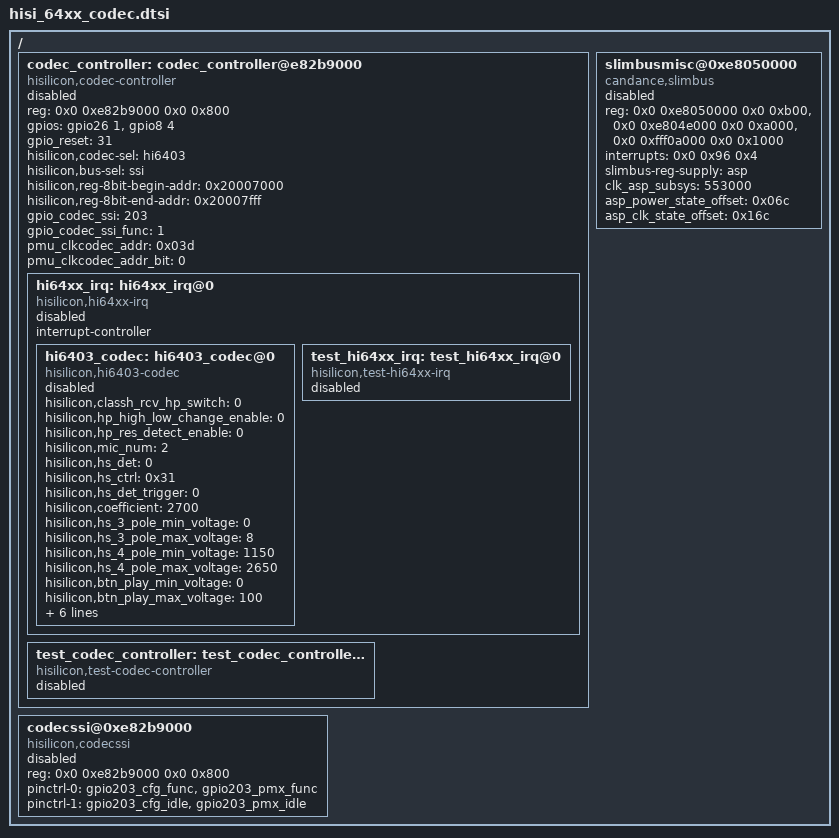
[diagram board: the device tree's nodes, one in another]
/*
 *  Copyright (C) 2014 Hisilicon Ltd.
 *
 *  This program is free software; you can redistribute it and/or modify
 *  it under the terms of the GNU General Public License version 2 as
 *  publishhed by the Free Software Foundation.
 */

/ {
	codec_controller: codec_controller@e82b9000 {
		compatible = "hisilicon,codec-controller";
		/* ssi base-addr & addr-range(0x200 << 2) */
		reg = <0x0 0xe82b9000 0x0 0x800>;
		/* irq & reset */
		gpios = <&gpio26 1 0>, <&gpio8 4 0>;
		gpio_reset = <31>; /* GPIO_031*/
		/* ssi pinctrl */
		/* select slimbus or ssi */
		hisilicon,codec-sel = "hi6403";
		hisilicon,bus-sel = "ssi";
		hisilicon,reg-8bit-begin-addr = <0x20007000>;
		hisilicon,reg-8bit-end-addr = <0x20007fff>;
		gpio_codec_ssi = <203>;
		gpio_codec_ssi_func = <1>;
		pmu_clkcodec_addr = <0x03d>;
		pmu_clkcodec_addr_bit = <0>;
		status = "disabled";

		hi64xx_irq: hi64xx_irq@0 {
			compatible = "hisilicon,hi64xx-irq";
			#interrupt-cells = <2>;
			interrupt-controller;
			status = "disabled";

			hi6403_codec: hi6403_codec@0{
				compatible = "hisilicon,hi6403-codec";
				hisilicon,classh_rcv_hp_switch = <0>;
				hisilicon,hp_high_low_change_enable = <0>;
				hisilicon,hp_res_detect_enable = <0>;
				hisilicon,mic_num = <2>;
				hisilicon,hs_det = <0>;
				hisilicon,hs_ctrl = <0x31>;
				hisilicon,hs_det_trigger = <0>;
				hisilicon,coefficient = <2700>;
				hisilicon,hs_3_pole_min_voltage = <0>;
				hisilicon,hs_3_pole_max_voltage = <8>;
				hisilicon,hs_4_pole_min_voltage = <1150>;
				hisilicon,hs_4_pole_max_voltage = <2650>;
				hisilicon,btn_play_min_voltage = <0>;
				hisilicon,btn_play_max_voltage = <100>;
				hisilicon,btn_voice_assistant_min_voltage = <110>;
				hisilicon,btn_voice_assistant_max_voltage = <180>;
				hisilicon,btn_volume_up_min_voltage = <181>;
				hisilicon,btn_volume_up_max_voltage = <320>;
				hisilicon,btn_volume_down_min_voltage = <320>;
				hisilicon,btn_volume_down_max_voltage = <700>;
				status = "disabled";
			};

			test_hi64xx_irq: test_hi64xx_irq@0 {
                               compatible = "hisilicon,test-hi64xx-irq";
                               status = "disabled";
			};
		};

		test_codec_controller: test_codec_controller@0 {
			compatible = "hisilicon,test-codec-controller";
			status = "disabled";
		};
	};
	codecssi@0xe82b9000 {
		compatible = "hisilicon,codecssi";
		reg = <0x0 0xe82b9000 0x0 0x800>;
		/* ssi pinctrl */
		pinctrl-names = "default", "idle";
		pinctrl-0 = <&gpio203_cfg_func &gpio203_pmx_func>;
		pinctrl-1 = <&gpio203_cfg_idle &gpio203_pmx_idle>;
		status = "disabled";
	};
	slimbusmisc@0xe8050000 {
		compatible = "candance,slimbus";
		reg = <0x0 0xe8050000 0x0 0xb00>,
			<0x0 0xe804e000 0x0 0xa000>,
			<0x0 0xfff0a000 0x0 0x1000>;
		interrupts = <0x0 0x96 0x4>;
		interrupt-names = "asp_irq_slimbus";
		slimbus-reg-supply = <&asp>;
		clk_asp_subsys = <553000>;
		asp_power_state_offset = <0x06c>;
		asp_clk_state_offset = < 0x16c>;
		status = "disabled";
	};
};
